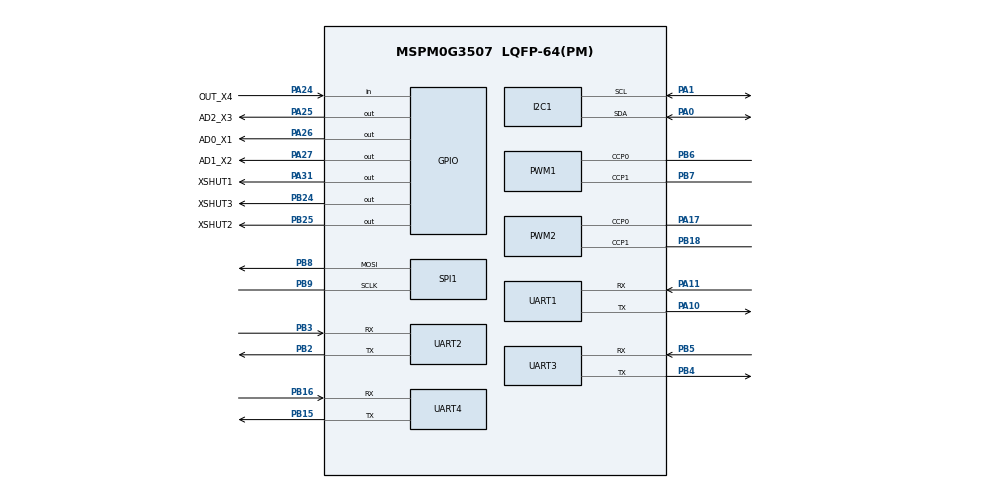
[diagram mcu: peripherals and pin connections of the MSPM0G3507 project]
/**
 * These arguments were used when this file was generated. They will be automatically applied on subsequent loads
 * via the GUI or CLI. Run CLI with '--help' for additional information on how to override these arguments.
 * @cliArgs --device "MSPM0G350X" --part "Default" --package "LQFP-64(PM)" --product "mspm0_sdk@2.02.00.05"
 * @v2CliArgs --device "MSPM0G3507" --package "LQFP-64(PM)" --product "mspm0_sdk@2.02.00.05"
 * @versions {"tool":"1.21.1+3772"}
 */

/**
 * Import the modules used in this configuration.
 */
const GPIO    = scripting.addModule("/ti/driverlib/GPIO", {}, false);
const GPIO1   = GPIO.addInstance();
const GPIO2   = GPIO.addInstance();
const GPIO3   = GPIO.addInstance();
const I2C     = scripting.addModule("/ti/driverlib/I2C", {}, false);
const I2C1    = I2C.addInstance();
const PWM     = scripting.addModule("/ti/driverlib/PWM", {}, false);
const PWM1    = PWM.addInstance();
const PWM2    = PWM.addInstance();
const SPI     = scripting.addModule("/ti/driverlib/SPI", {}, false);
const SPI1    = SPI.addInstance();
const SYSCTL  = scripting.addModule("/ti/driverlib/SYSCTL");
const SYSTICK = scripting.addModule("/ti/driverlib/SYSTICK");
const TIMER   = scripting.addModule("/ti/driverlib/TIMER", {}, false);
const TIMER1  = TIMER.addInstance();
const UART    = scripting.addModule("/ti/driverlib/UART", {}, false);
const UART1   = UART.addInstance();
const UART2   = UART.addInstance();
const UART3   = UART.addInstance();
const UART4   = UART.addInstance();

/**
 * Write custom configuration values to the imported modules.
 */
const divider6       = system.clockTree["PLL_CLK2X_DIV"];
divider6.divideValue = 4;

const divider7       = system.clockTree["PLL_PDIV"];
divider7.divideValue = 2;

const divider9       = system.clockTree["UDIV"];
divider9.divideValue = 2;

const gate7  = system.clockTree["MFCLKGATE"];
gate7.enable = true;

const multiplier2         = system.clockTree["PLL_QDIV"];
multiplier2.multiplyValue = 10;

const mux8       = system.clockTree["HSCLKMUX"];
mux8.inputSelect = "HSCLKMUX_SYSPLL2X";

GPIO1.$name                         = "XSHUT";
GPIO1.associatedPins.create(3);
GPIO1.associatedPins[0].$name       = "XSHUT1";
GPIO1.associatedPins[0].pin.$assign = "PA31";
GPIO1.associatedPins[1].$name       = "XSHUT2";
GPIO1.associatedPins[1].pin.$assign = "PB25";
GPIO1.associatedPins[2].$name       = "XSHUT3";
GPIO1.associatedPins[2].pin.$assign = "PB24";

const Board = scripting.addModule("/ti/driverlib/Board", {}, false);

GPIO2.$name                         = "LINE_FOLLOW";
GPIO2.associatedPins.create(4);
GPIO2.associatedPins[0].$name       = "AD0_X1";
GPIO2.associatedPins[0].pin.$assign = "PA26";
GPIO2.associatedPins[1].$name       = "AD1_X2";
GPIO2.associatedPins[1].pin.$assign = "PA27";
GPIO2.associatedPins[2].$name       = "AD2_X3";
GPIO2.associatedPins[2].pin.$assign = "PA25";
GPIO2.associatedPins[3].$name       = "OUT_X4";
GPIO2.associatedPins[3].direction   = "INPUT";
GPIO2.associatedPins[3].pin.$assign = "PA24";

GPIO3.$name                          = "LCD";
GPIO3.associatedPins.create(4);
GPIO3.associatedPins[0].$name        = "RES";
GPIO3.associatedPins[0].ioStructure  = "SD";
GPIO3.associatedPins[0].assignedPort = "PORTB";
GPIO3.associatedPins[0].assignedPin  = "10";
GPIO3.associatedPins[1].$name        = "DC";
GPIO3.associatedPins[1].ioStructure  = "SD";
GPIO3.associatedPins[1].assignedPort = "PORTB";
GPIO3.associatedPins[1].assignedPin  = "11";
GPIO3.associatedPins[2].$name        = "CS";
GPIO3.associatedPins[2].ioStructure  = "SD";
GPIO3.associatedPins[2].assignedPort = "PORTB";
GPIO3.associatedPins[2].assignedPin  = "14";
GPIO3.associatedPins[3].$name        = "BLK";
GPIO3.associatedPins[3].ioStructure  = "SD";
GPIO3.associatedPins[3].assignedPort = "PORTB";
GPIO3.associatedPins[3].assignedPin  = "26";

I2C1.$name                             = "I2C_VL53L0X";
I2C1.peripheral.$assign                = "I2C0";
I2C1.peripheral.sdaPin.$assign         = "PA0";
I2C1.peripheral.sclPin.$assign         = "PA1";
I2C1.sdaPinConfig.hideOutputInversion  = scripting.forceWrite(false);
I2C1.sdaPinConfig.onlyInternalResistor = scripting.forceWrite(false);
I2C1.sdaPinConfig.passedPeripheralType = scripting.forceWrite("Digital");
I2C1.sdaPinConfig.$name                = "ti_driverlib_gpio_GPIOPinGeneric8";
I2C1.sclPinConfig.hideOutputInversion  = scripting.forceWrite(false);
I2C1.sclPinConfig.onlyInternalResistor = scripting.forceWrite(false);
I2C1.sclPinConfig.passedPeripheralType = scripting.forceWrite("Digital");
I2C1.sclPinConfig.$name                = "ti_driverlib_gpio_GPIOPinGeneric9";

PWM1.$name                      = "PWM_0";
PWM1.pwmMode                    = "EDGE_ALIGN_UP";
PWM1.clockPrescale              = 160;
PWM1.timerCount                 = 10000;
PWM1.peripheral.$assign         = "TIMG6";
PWM1.peripheral.ccp0Pin.$assign = "PB6";
PWM1.peripheral.ccp1Pin.$assign = "PB7";
PWM1.PWM_CHANNEL_0.$name        = "ti_driverlib_pwm_PWMTimerCC0";
PWM1.PWM_CHANNEL_0.dutyCycle    = 50;
PWM1.PWM_CHANNEL_1.$name        = "ti_driverlib_pwm_PWMTimerCC1";
PWM1.ccp0PinConfig.$name        = "ti_driverlib_gpio_GPIOPinGeneric10";
PWM1.ccp1PinConfig.$name        = "ti_driverlib_gpio_GPIOPinGeneric11";

PWM2.clockPrescale                      = 160;
PWM2.timerCount                         = 10000;
PWM2.$name                              = "SERVO_1";
PWM2.peripheral.$assign                 = "TIMA1";
PWM2.peripheral.ccp0Pin.$assign         = "PA17";
PWM2.peripheral.ccp1Pin.$assign         = "PB18";
PWM2.PWM_CHANNEL_0.$name                = "ti_driverlib_pwm_PWMTimerCC2";
PWM2.PWM_CHANNEL_1.$name                = "ti_driverlib_pwm_PWMTimerCC3";
PWM2.ccp0PinConfig.direction            = scripting.forceWrite("OUTPUT");
PWM2.ccp0PinConfig.hideOutputInversion  = scripting.forceWrite(false);
PWM2.ccp0PinConfig.onlyInternalResistor = scripting.forceWrite(false);
PWM2.ccp0PinConfig.passedPeripheralType = scripting.forceWrite("Digital");
PWM2.ccp0PinConfig.$name                = "ti_driverlib_gpio_GPIOPinGeneric12";
PWM2.ccp1PinConfig.direction            = scripting.forceWrite("OUTPUT");
PWM2.ccp1PinConfig.hideOutputInversion  = scripting.forceWrite(false);
PWM2.ccp1PinConfig.onlyInternalResistor = scripting.forceWrite(false);
PWM2.ccp1PinConfig.passedPeripheralType = scripting.forceWrite("Digital");
PWM2.ccp1PinConfig.$name                = "ti_driverlib_gpio_GPIOPinGeneric13";

SPI1.$name                              = "SPI_LCD";
SPI1.targetBitRate                      = 20000000;
SPI1.frameFormat                        = "MOTO3";
SPI1.peripheral.$assign                 = "SPI1";
SPI1.peripheral.sclkPin.$assign         = "PB9";
SPI1.peripheral.mosiPin.$assign         = "PB8";
SPI1.sclkPinConfig.$name                = "ti_driverlib_gpio_GPIOPinGeneric16";
SPI1.sclkPinConfig.direction            = scripting.forceWrite("OUTPUT");
SPI1.sclkPinConfig.onlyInternalResistor = scripting.forceWrite(false);
SPI1.sclkPinConfig.passedPeripheralType = scripting.forceWrite("Digital");
SPI1.mosiPinConfig.$name                = "ti_driverlib_gpio_GPIOPinGeneric17";
SPI1.mosiPinConfig.direction            = scripting.forceWrite("OUTPUT");
SPI1.mosiPinConfig.hideOutputInversion  = scripting.forceWrite(false);
SPI1.mosiPinConfig.onlyInternalResistor = scripting.forceWrite(false);
SPI1.mosiPinConfig.passedPeripheralType = scripting.forceWrite("Digital");
SPI1.misoPinConfig.$name                = "ti_driverlib_gpio_GPIOPinGeneric18";
SPI1.misoPinConfig.onlyInternalResistor = scripting.forceWrite(false);
SPI1.misoPinConfig.passedPeripheralType = scripting.forceWrite("Digital");

SYSCTL.forceDefaultClkConfig = true;
SYSCTL.clockTreeEn           = true;

SYSTICK.periodEnable      = true;
SYSTICK.interruptEnable   = true;
SYSTICK.systickEnable     = true;
SYSTICK.period            = 80000;
SYSTICK.interruptPriority = "3";

TIMER1.$name              = "TIMER_0";
TIMER1.timerClkSrc        = "MFCLK";
TIMER1.interruptPriority  = "2";
TIMER1.timerMode          = "PERIODIC_UP";
TIMER1.timerPeriod        = "1ms";
TIMER1.interrupts         = ["LOAD","ZERO"];
TIMER1.peripheral.$assign = "TIMA0";

UART1.$name                            = "user";
UART1.uartClkSrc                       = "MFCLK";
UART1.targetBaudRate                   = 115200;
UART1.peripheral.rxPin.$assign         = "PA11";
UART1.peripheral.txPin.$assign         = "PA10";
UART1.txPinConfig.direction            = scripting.forceWrite("OUTPUT");
UART1.txPinConfig.hideOutputInversion  = scripting.forceWrite(false);
UART1.txPinConfig.onlyInternalResistor = scripting.forceWrite(false);
UART1.txPinConfig.passedPeripheralType = scripting.forceWrite("Digital");
UART1.txPinConfig.$name                = "ti_driverlib_gpio_GPIOPinGeneric0";
UART1.rxPinConfig.hideOutputInversion  = scripting.forceWrite(false);
UART1.rxPinConfig.onlyInternalResistor = scripting.forceWrite(false);
UART1.rxPinConfig.passedPeripheralType = scripting.forceWrite("Digital");
UART1.rxPinConfig.$name                = "ti_driverlib_gpio_GPIOPinGeneric1";

UART2.$name                            = "MSPMotor";
UART2.targetBaudRate                   = 115200;
UART2.uartClkSrc                       = "MFCLK";
UART2.enabledInterrupts                = ["RX"];
UART2.interruptPriority                = "0";
UART2.peripheral.$assign               = "UART3";
UART2.peripheral.rxPin.$assign         = "PB3";
UART2.peripheral.txPin.$assign         = "PB2";
UART2.txPinConfig.direction            = scripting.forceWrite("OUTPUT");
UART2.txPinConfig.hideOutputInversion  = scripting.forceWrite(false);
UART2.txPinConfig.onlyInternalResistor = scripting.forceWrite(false);
UART2.txPinConfig.passedPeripheralType = scripting.forceWrite("Digital");
UART2.txPinConfig.$name                = "ti_driverlib_gpio_GPIOPinGeneric2";
UART2.rxPinConfig.hideOutputInversion  = scripting.forceWrite(false);
UART2.rxPinConfig.onlyInternalResistor = scripting.forceWrite(false);
UART2.rxPinConfig.passedPeripheralType = scripting.forceWrite("Digital");
UART2.rxPinConfig.$name                = "ti_driverlib_gpio_GPIOPinGeneric3";

UART3.$name                            = "IMU";
UART3.targetBaudRate                   = 115200;
UART3.enabledInterrupts                = ["RX"];
UART3.interruptPriority                = "1";
UART3.peripheral.rxPin.$assign         = "PB5";
UART3.peripheral.txPin.$assign         = "PB4";
UART3.txPinConfig.direction            = scripting.forceWrite("OUTPUT");
UART3.txPinConfig.hideOutputInversion  = scripting.forceWrite(false);
UART3.txPinConfig.onlyInternalResistor = scripting.forceWrite(false);
UART3.txPinConfig.passedPeripheralType = scripting.forceWrite("Digital");
UART3.txPinConfig.$name                = "ti_driverlib_gpio_GPIOPinGeneric4";
UART3.rxPinConfig.hideOutputInversion  = scripting.forceWrite(false);
UART3.rxPinConfig.onlyInternalResistor = scripting.forceWrite(false);
UART3.rxPinConfig.passedPeripheralType = scripting.forceWrite("Digital");
UART3.rxPinConfig.$name                = "ti_driverlib_gpio_GPIOPinGeneric5";

UART4.$name                            = "Vision";
UART4.targetBaudRate                   = 115200;
UART4.peripheral.rxPin.$assign         = "PB16";
UART4.peripheral.txPin.$assign         = "PB15";
UART4.txPinConfig.direction            = scripting.forceWrite("OUTPUT");
UART4.txPinConfig.hideOutputInversion  = scripting.forceWrite(false);
UART4.txPinConfig.onlyInternalResistor = scripting.forceWrite(false);
UART4.txPinConfig.passedPeripheralType = scripting.forceWrite("Digital");
UART4.txPinConfig.$name                = "ti_driverlib_gpio_GPIOPinGeneric6";
UART4.rxPinConfig.hideOutputInversion  = scripting.forceWrite(false);
UART4.rxPinConfig.onlyInternalResistor = scripting.forceWrite(false);
UART4.rxPinConfig.passedPeripheralType = scripting.forceWrite("Digital");
UART4.rxPinConfig.$name                = "ti_driverlib_gpio_GPIOPinGeneric7";

/**
 * Pinmux solution for unlocked pins/peripherals. This ensures that minor changes to the automatic solver in a future
 * version of the tool will not impact the pinmux you originally saw.  These lines can be completely deleted in order to
 * re-solve from scratch.
 */
Board.peripheral.$suggestSolution            = "DEBUGSS";
Board.peripheral.swclkPin.$suggestSolution   = "PA20";
Board.peripheral.swdioPin.$suggestSolution   = "PA19";
GPIO3.associatedPins[0].pin.$suggestSolution = "PB10";
GPIO3.associatedPins[1].pin.$suggestSolution = "PB11";
GPIO3.associatedPins[2].pin.$suggestSolution = "PB14";
GPIO3.associatedPins[3].pin.$suggestSolution = "PB26";
SPI1.peripheral.misoPin.$suggestSolution     = "PA16";
UART1.peripheral.$suggestSolution            = "UART0";
UART3.peripheral.$suggestSolution            = "UART1";
UART4.peripheral.$suggestSolution            = "UART2";
